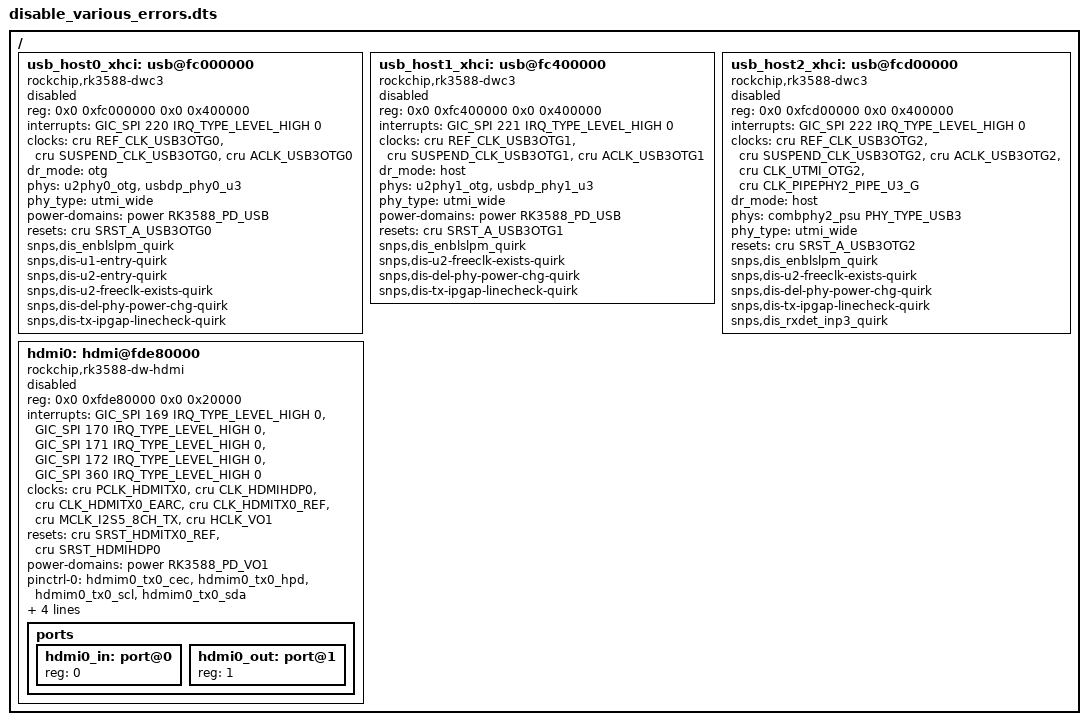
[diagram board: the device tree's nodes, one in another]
/ {
	usb_host0_xhci: usb@fc000000 {
		compatible = "rockchip,rk3588-dwc3", "snps,dwc3";
		reg = <0x0 0xfc000000 0x0 0x400000>;
		interrupts = <GIC_SPI 220 IRQ_TYPE_LEVEL_HIGH 0>;
		clocks = <&cru REF_CLK_USB3OTG0>, <&cru SUSPEND_CLK_USB3OTG0>,
			 <&cru ACLK_USB3OTG0>;
		clock-names = "ref_clk", "suspend_clk", "bus_clk";
		dr_mode = "otg";
		phys = <&u2phy0_otg>, <&usbdp_phy0_u3>;
		phy-names = "usb2-phy", "usb3-phy";
		phy_type = "utmi_wide";
		power-domains = <&power RK3588_PD_USB>;
		resets = <&cru SRST_A_USB3OTG0>;
		snps,dis_enblslpm_quirk;
		snps,dis-u1-entry-quirk;
		snps,dis-u2-entry-quirk;
		snps,dis-u2-freeclk-exists-quirk;
		snps,dis-del-phy-power-chg-quirk;
		snps,dis-tx-ipgap-linecheck-quirk;
		status = "disabled";
	};

	usb_host1_xhci: usb@fc400000 {
		compatible = "rockchip,rk3588-dwc3", "snps,dwc3";
		reg = <0x0 0xfc400000 0x0 0x400000>;
		interrupts = <GIC_SPI 221 IRQ_TYPE_LEVEL_HIGH 0>;
		clocks = <&cru REF_CLK_USB3OTG1>, <&cru SUSPEND_CLK_USB3OTG1>,
			 <&cru ACLK_USB3OTG1>;
		clock-names = "ref_clk", "suspend_clk", "bus_clk";
		dr_mode = "host";
		phys = <&u2phy1_otg>, <&usbdp_phy1_u3>;
		phy-names = "usb2-phy", "usb3-phy";
		phy_type = "utmi_wide";
		power-domains = <&power RK3588_PD_USB>;
		resets = <&cru SRST_A_USB3OTG1>;
		snps,dis_enblslpm_quirk;
		snps,dis-u2-freeclk-exists-quirk;
		snps,dis-del-phy-power-chg-quirk;
		snps,dis-tx-ipgap-linecheck-quirk;
		status = "disabled";
	};

	usb_host2_xhci: usb@fcd00000 {
		compatible = "rockchip,rk3588-dwc3", "snps,dwc3";
		reg = <0x0 0xfcd00000 0x0 0x400000>;
		interrupts = <GIC_SPI 222 IRQ_TYPE_LEVEL_HIGH 0>;
		clocks = <&cru REF_CLK_USB3OTG2>, <&cru SUSPEND_CLK_USB3OTG2>,
			 <&cru ACLK_USB3OTG2>, <&cru CLK_UTMI_OTG2>,
			 <&cru CLK_PIPEPHY2_PIPE_U3_G>;
		clock-names = "ref_clk", "suspend_clk", "bus_clk", "utmi", "pipe";
		dr_mode = "host";
		phys = <&combphy2_psu PHY_TYPE_USB3>;
		phy-names = "usb3-phy";
		phy_type = "utmi_wide";
		resets = <&cru SRST_A_USB3OTG2>;
		snps,dis_enblslpm_quirk;
		snps,dis-u2-freeclk-exists-quirk;
		snps,dis-del-phy-power-chg-quirk;
		snps,dis-tx-ipgap-linecheck-quirk;
		snps,dis_rxdet_inp3_quirk;
		status = "disabled";
	};
	
	hdmi0: hdmi@fde80000 {
		compatible = "rockchip,rk3588-dw-hdmi";
		reg = <0x0 0xfde80000 0x0 0x20000>;
		interrupts = <GIC_SPI 169 IRQ_TYPE_LEVEL_HIGH 0>,
			     <GIC_SPI 170 IRQ_TYPE_LEVEL_HIGH 0>,
			     <GIC_SPI 171 IRQ_TYPE_LEVEL_HIGH 0>,
			     <GIC_SPI 172 IRQ_TYPE_LEVEL_HIGH 0>,
			     <GIC_SPI 360 IRQ_TYPE_LEVEL_HIGH 0>;
		clocks = <&cru PCLK_HDMITX0>,
			 <&cru CLK_HDMIHDP0>,
			 <&cru CLK_HDMITX0_EARC>,
			 <&cru CLK_HDMITX0_REF>,
			 <&cru MCLK_I2S5_8CH_TX>,
			 <&cru HCLK_VO1>;
		clock-names = "pclk",
			      "hpd",
			      "earc",
			      "hdmitx_ref",
			      "aud",
			      "hclk_vo1";
		resets = <&cru SRST_HDMITX0_REF>, <&cru SRST_HDMIHDP0>;
		reset-names = "ref", "hdp";
		power-domains = <&power RK3588_PD_VO1>;
		pinctrl-names = "default";
		pinctrl-0 = <&hdmim0_tx0_cec &hdmim0_tx0_hpd &hdmim0_tx0_scl &hdmim0_tx0_sda>;
		reg-io-width = <4>;
		rockchip,grf = <&sys_grf>;
		rockchip,vo1_grf = <&vo1_grf>;
		phys = <&hdptxphy_hdmi0>;
		phy-names = "hdmi";
		#sound-dai-cells = <0>;
		status = "disabled";

		ports {
			#address-cells = <1>;
			#size-cells = <0>;

			hdmi0_in: port@0 {
				reg = <0>;
			};

			hdmi0_out: port@1 {
				reg = <1>;
			};

		};
	};
};
